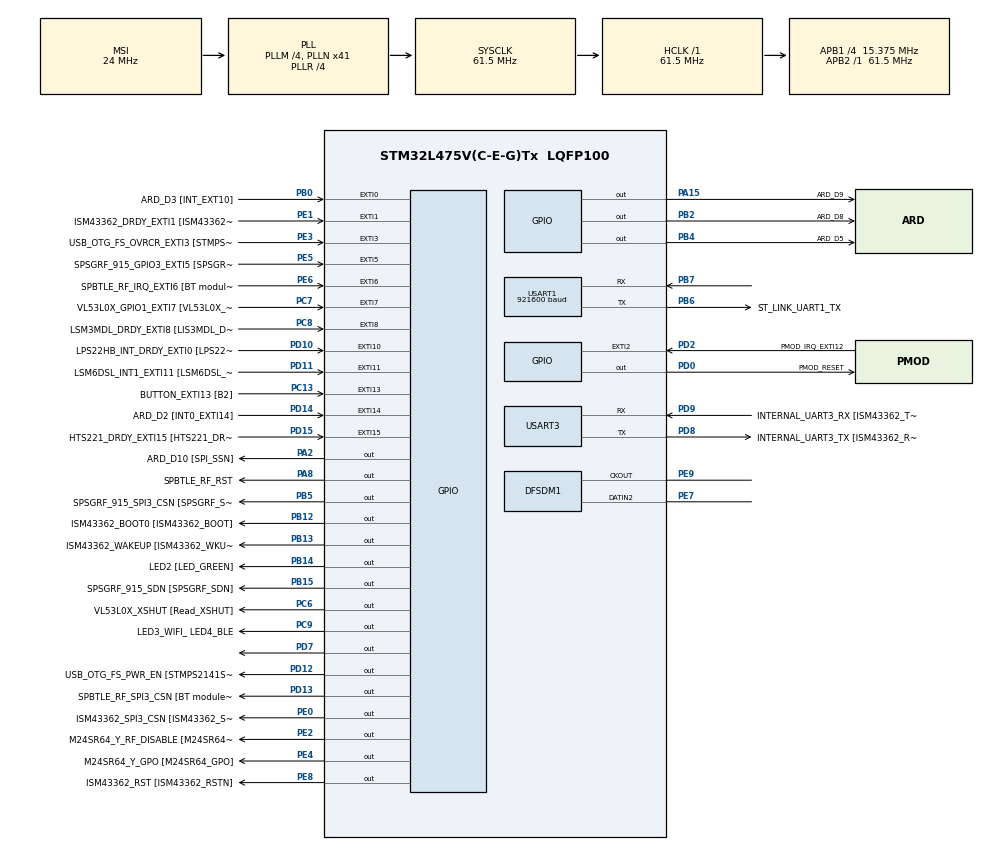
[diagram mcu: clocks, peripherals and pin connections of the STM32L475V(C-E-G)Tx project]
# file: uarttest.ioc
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DFSDM1.Divider=20
DFSDM1.DmaMode_reg_FIL0=ENABLE
DFSDM1.FastMode_reg_FIL0=ENABLE
DFSDM1.Filter_regChannel_FIL0=DFSDM_CHANNEL_1
DFSDM1.Fosr_FIL0=64
DFSDM1.Oversampling_CH1=1
DFSDM1.RightBitShift_CH1=0x02
DFSDM1.Selection=DFSDM_CHANNEL_OUTPUT_CLOCK_AUDIO
DFSDM1.SincOrder_FIL0=DFSDM_FILTER_SINC4_ORDER
DFSDM1.SpiClock_internal_CH1=DFSDM_CHANNEL_SPI_CLOCK_INTERNAL_DIV2_FALLING
Dma.DFSDM1_FLT0.0.Direction=DMA_PERIPH_TO_MEMORY
Dma.DFSDM1_FLT0.0.Instance=DMA1_Channel4
Dma.DFSDM1_FLT0.0.MemDataAlignment=DMA_MDATAALIGN_WORD
Dma.DFSDM1_FLT0.0.MemInc=DMA_MINC_ENABLE
Dma.DFSDM1_FLT0.0.Mode=DMA_CIRCULAR
Dma.DFSDM1_FLT0.0.PeriphDataAlignment=DMA_PDATAALIGN_WORD
Dma.DFSDM1_FLT0.0.PeriphInc=DMA_PINC_DISABLE
Dma.DFSDM1_FLT0.0.Priority=DMA_PRIORITY_HIGH
Dma.Request0=DFSDM1_FLT0
Mcu.Family=STM32L4
Mcu.Name=STM32L475V(C-E-G)Tx
Mcu.Package=LQFP100
NVIC.DFSDM1_FLT0_IRQn=true\:0\:0\:false\:false\:true\:true\:true\:true
NVIC.DMA1_Channel4_IRQn=true\:0\:0\:false\:false\:true\:false\:true\:true
NVIC.EXTI15_10_IRQn=true\:0\:0\:false\:false\:true\:true\:true\:true
NVIC.EXTI9_5_IRQn=true\:0\:0\:false\:false\:true\:true\:true\:true
NVIC.PriorityGroup=NVIC_PRIORITYGROUP_4
PA13\ (JTMS-SWDIO).GPIO_Label=SYS_JTMS_SWDIO
PA13\ (JTMS-SWDIO).Mode=Serial_Wire
PA13\ (JTMS-SWDIO).Signal=SYS_JTMS-SWDIO
PA14\ (JTCK-SWCLK).GPIO_Label=SYS_JTCK_SWCLK
PA14\ (JTCK-SWCLK).Mode=Serial_Wire
PA14\ (JTCK-SWCLK).Signal=SYS_JTCK-SWCLK
PA15\ (JTDI).GPIO_Label=ARD_D9
PA15\ (JTDI).Signal=GPIO_Output
PA2.GPIO_Label=ARD_D10 [SPI_SSN]
PA2.Signal=GPIO_Output
PA8.GPIO_Label=SPBTLE_RF_RST
PA8.Signal=GPIO_Output
PB0.GPIO_Label=ARD_D3 [INT_EXT10]
PB0.Signal=GPXTI0
PB12.GPIO_Label=ISM43362_BOOT0 [ISM43362_BOOT]
PB12.Signal=GPIO_Output
PB13.GPIO_Label=ISM43362_WAKEUP [ISM43362_WKUP]
PB13.Signal=GPIO_Output
PB14.GPIO_Label=LED2 [LED_GREEN]
PB14.Signal=GPIO_Output
PB15.GPIO_Label=SPSGRF_915_SDN [SPSGRF_SDN]
PB15.Signal=GPIO_Output
PB2.GPIO_Label=ARD_D8
PB2.Signal=GPIO_Output
PB4\ (NJTRST).GPIO_Label=ARD_D5
PB4\ (NJTRST).Signal=GPIO_Output
PB5.GPIO_Label=SPSGRF_915_SPI3_CSN [SPSGRF_SPI_CS]
PB5.PinState=GPIO_PIN_SET
PB5.Signal=GPIO_Output
PB6.GPIO_Label=ST_LINK_UART1_TX
PB6.Mode=Asynchronous
PB6.Signal=USART1_TX
PB7.Mode=Asynchronous
PB7.Signal=USART1_RX
PC13.GPIO_Label=BUTTON_EXTI13 [B2]
PC13.GPIO_ModeDefaultEXTI=GPIO_MODE_IT_FALLING
PC13.Signal=GPXTI13
PC14-OSC32_IN\ (PC14).Mode=LSE-External-Oscillator
PC14-OSC32_IN\ (PC14).Signal=RCC_OSC32_IN
PC15-OSC32_OUT\ (PC15).Mode=LSE-External-Oscillator
PC15-OSC32_OUT\ (PC15).Signal=RCC_OSC32_OUT
PC6.GPIO_Label=VL53L0X_XSHUT [Read_XSHUT]
PC6.Signal=GPIO_Output
PC7.GPIO_Label=VL53L0X_GPIO1_EXTI7 [VL53L0X_GPIO1]
PC7.Signal=GPXTI7
PC8.GPIO_Label=LSM3MDL_DRDY_EXTI8 [LIS3MDL_DRDY]
PC8.Signal=GPXTI8
PC9.GPIO_Label=LED3_WIFI_ LED4_BLE
PC9.Signal=GPIO_Output
PD0.GPIO_Label=PMOD_RESET
PD0.Signal=GPIO_Output
PD10.GPIO_Label=LPS22HB_INT_DRDY_EXTI0 [LPS22HB_INT_DRDY] 
PD10.Signal=GPXTI10
PD11.GPIO_Label=LSM6DSL_INT1_EXTI11 [LSM6DSL_INT1]
PD11.Signal=GPXTI11
PD12.GPIO_Label=USB_OTG_FS_PWR_EN [STMPS2141STR_EN]
PD12.Signal=GPIO_Output
PD13.GPIO_Label=SPBTLE_RF_SPI3_CSN [BT module_SPI_CS]
PD13.PinState=GPIO_PIN_SET
PD13.Signal=GPIO_Output
PD14.GPIO_Label=ARD_D2 [INT0_EXTI14]
PD14.Signal=GPXTI14
PD15.GPIO_Label=HTS221_DRDY_EXTI15 [HTS221_DRDY]
PD15.Signal=GPXTI15
PD2.GPIO_Label=PMOD_IRQ_EXTI12
PD2.Signal=GPXTI2
PD7.Signal=GPIO_Output
PD8.GPIO_Label=INTERNAL_UART3_TX [ISM43362_RX]
PD8.Mode=Asynchronous
PD8.Signal=USART3_TX
PD9.GPIO_Label=INTERNAL_UART3_RX [ISM43362_TX]
PD9.Mode=Asynchronous
PD9.Signal=USART3_RX
PE0.GPIO_Label=ISM43362_SPI3_CSN [ISM43362_SSN]
PE0.PinState=GPIO_PIN_SET
PE0.Signal=GPIO_Output
PE1.GPIO_Label=ISM43362_DRDY_EXTI1 [ISM43362_DATARDY]
PE1.Signal=GPXTI1
PE2.GPIO_Label=M24SR64_Y_RF_DISABLE [M24SR64_RFDIS]
PE2.Signal=GPIO_Output
PE3.GPIO_Label=USB_OTG_FS_OVRCR_EXTI3 [STMPS2141STR_FAULT]
PE3.Signal=GPXTI3
PE4.GPIO_Label=M24SR64_Y_GPO [M24SR64_GPO]
PE4.Signal=GPIO_Output
PE5.GPIO_Label=SPSGRF_915_GPIO3_EXTI5 [SPSGRF_GPIO_3]
PE5.Signal=GPXTI5
PE6.GPIO_Label=SPBTLE_RF_IRQ_EXTI6 [BT module_SPI_IRQ]
PE6.Signal=GPXTI6
PE7.Signal=S_DATAIN2DFSDM1
PE8.GPIO_Label=ISM43362_RST [ISM43362_RSTN]
PE8.Signal=GPIO_Output
PE9.Signal=S_CKOUTDFSDM1
ProjectManager.HeapSize=0x200
ProjectManager.StackSize=0x400
ProjectManager.TargetToolchain=STM32CubeIDE
RCC.ADCFreq_Value=33000000
RCC.AHBFreq_Value=61500000
RCC.APB1CLKDivider=RCC_HCLK_DIV4
RCC.APB1Freq_Value=15375000
RCC.APB1TimFreq_Value=30750000
RCC.APB2Freq_Value=61500000
RCC.APB2TimFreq_Value=61500000
RCC.CortexFreq_Value=61500000
RCC.HCLKFreq_Value=61500000
RCC.HSE_VALUE=8000000
RCC.HSI_VALUE=16000000
RCC.MSIClockRange=RCC_MSIRANGE_9
RCC.MSI_VALUE=24000000
RCC.PLLM=4
RCC.PLLN=41
RCC.PLLR=RCC_PLLR_DIV4
RCC.PLLSAI1N=11
RCC.SYSCLKFreq_VALUE=61500000
RCC.SYSCLKSource=RCC_SYSCLKSOURCE_PLLCLK
RCC.USART1CLockSelection=RCC_USART1CLKSOURCE_SYSCLK
RCC.USART3CLockSelection=RCC_USART3CLKSOURCE_SYSCLK
RCC.USBFreq_Value=33000000
RCC.VCOOutputFreq_Value=246000000
SH.S_CKOUTDFSDM1.0=DFSDM1_CKOUT
SH.S_CKOUTDFSDM1.1=DFSDM1_CKOUT,PDM_SPI_Input_from_ch12_and_Internal_Clock
SH.S_CKOUTDFSDM1.2=DFSDM1_CKOUT
SH.S_DATAIN2DFSDM1.0=DFSDM1_DATIN2,PDM_SPI_Input_from_ch12_and_Internal_Clock
SH.S_DATAIN2DFSDM1.1=DFSDM1_DATIN2
USART1.BaudRate=921600
USART1.VirtualMode-Asynchronous=VM_ASYNC
USART3.VirtualMode-Asynchronous=VM_ASYNC
VP_CRC_VS_CRC.Mode=CRC_Activate
board=B-L475E-IOT01A2

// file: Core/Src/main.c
/* USER CODE BEGIN Header */
/**
  ******************************************************************************
  * @file           : main.c
  * @brief          : Main program body
  ******************************************************************************
  * @attention
  *
  * Copyright (c) 2024 STMicroelectronics.
  * All rights reserved.
  *
  * This software is licensed under terms that can be found in the LICENSE file
  * in the root directory of this software component.
  * If no LICENSE file comes with this software, it is provided AS-IS.
  *
  ******************************************************************************
  */
/* USER CODE END Header */
#include "main.h"
//////////////////
#include "stm32l4xx_hal.h"
//#include "arm_math.h"

CRC_HandleTypeDef hcrc;

DFSDM_Filter_HandleTypeDef hdfsdm1_filter0;
DFSDM_Channel_HandleTypeDef hdfsdm1_channel1;
DMA_HandleTypeDef hdma_dfsdm1_flt0;

UART_HandleTypeDef huart1;
UART_HandleTypeDef huart3;

void SystemClock_Config(void);
static void MX_GPIO_Init(void);
static void MX_DMA_Init(void);
static void MX_DFSDM1_Init(void);
static void MX_USART1_UART_Init(void);
static void MX_USART3_UART_Init(void);
static void MX_CRC_Init(void);
/* USER CODE BEGIN PFP */

void PDM_to_PCM(int32_t *pdm_data, int16_t *pcm_data, uint16_t pdm_size);
/* USER CODE END PFP */

int main(void)
{

  /* MCU Configuration--------------------------------------------------------*/

  /* Reset of all peripherals, Initializes the Flash interface and the Systick. */
  HAL_Init();

  /* Configure the system clock */
  SystemClock_Config();

  /* Initialize all configured peripherals */
  MX_GPIO_Init();
  MX_DMA_Init();
  MX_DFSDM1_Init();
  MX_USART1_UART_Init();
  MX_USART3_UART_Init();
  MX_CRC_Init();
  /* USER CODE BEGIN 2 */
#define PDM_BUFFER_SIZE 64
#define PCM_BUFFER_SIZE (PDM_BUFFER_SIZE / 4)
int32_t pdm_buffer[PDM_BUFFER_SIZE];
int16_t pcm_buffer[PCM_BUFFER_SIZE];
HAL_DFSDM_FilterRegularStart_DMA(&hdfsdm1_filter0, pdm_buffer, PDM_BUFFER_SIZE);
/* USER CODE END 2 */

  /* Infinite loop */
  while (1)
  {

  }
}
void HAL_DFSDM_FilterRegConvCpltCallback(DFSDM_Filter_HandleTypeDef *hdfsdm_filter) {
    // Convert PDM to PCM
    PDM_to_PCM(pdm_buffer, pcm_buffer, PDM_BUFFER_SIZE);
    // Transmit PCM data via UART1
    HAL_UART_Transmit(&huart1, (uint8_t*)pcm_buffer, sizeof(pcm_buffer), HAL_MAX_DELAY);
}

    void PDM_to_PCM(int32_t *pdm_data, int16_t *pcm_data, uint16_t pdm_size) {
     // Example conversion function (implement as needed)
      for (uint16_t i = 0; i < pdm_size / 4; i++) {
            pcm_data[i] = (int16_t)(pdm_data[i] >> 8); // Simple downsampling
      }
    }

void SystemClock_Config(void)
{
  RCC_OscInitTypeDef RCC_OscInitStruct = {0};
  RCC_ClkInitTypeDef RCC_ClkInitStruct = {0};

  /** Configure the main internal regulator output voltage
  */
  if (HAL_PWREx_ControlVoltageScaling(PWR_REGULATOR_VOLTAGE_SCALE1) != HAL_OK)
  {
    Error_Handler();
  }

  /** Configure LSE Drive Capability
  */
  HAL_PWR_EnableBkUpAccess();
  __HAL_RCC_LSEDRIVE_CONFIG(RCC_LSEDRIVE_LOW);

  /** Initializes the RCC Oscillators according to the specified parameters
  * in the RCC_OscInitTypeDef structure.
  */
  RCC_OscInitStruct.OscillatorType = RCC_OSCILLATORTYPE_LSE|RCC_OSCILLATORTYPE_MSI;
  RCC_OscInitStruct.LSEState = RCC_LSE_ON;
  RCC_OscInitStruct.MSIState = RCC_MSI_ON;
  RCC_OscInitStruct.MSICalibrationValue = 0;
  RCC_OscInitStruct.MSIClockRange = RCC_MSIRANGE_9;
  RCC_OscInitStruct.PLL.PLLState = RCC_PLL_ON;
  RCC_OscInitStruct.PLL.PLLSource = RCC_PLLSOURCE_MSI;
  RCC_OscInitStruct.PLL.PLLM = 4;
  RCC_OscInitStruct.PLL.PLLN = 41;
  RCC_OscInitStruct.PLL.PLLP = RCC_PLLP_DIV7;
  RCC_OscInitStruct.PLL.PLLQ = RCC_PLLQ_DIV2;
  RCC_OscInitStruct.PLL.PLLR = RCC_PLLR_DIV4;
  if (HAL_RCC_OscConfig(&RCC_OscInitStruct) != HAL_OK)
  {
    Error_Handler();
  }

  /** Initializes the CPU, AHB and APB buses clocks
  */
  RCC_ClkInitStruct.ClockType = RCC_CLOCKTYPE_HCLK|RCC_CLOCKTYPE_SYSCLK
                              |RCC_CLOCKTYPE_PCLK1|RCC_CLOCKTYPE_PCLK2;
  RCC_ClkInitStruct.SYSCLKSource = RCC_SYSCLKSOURCE_PLLCLK;
  RCC_ClkInitStruct.AHBCLKDivider = RCC_SYSCLK_DIV1;
  RCC_ClkInitStruct.APB1CLKDivider = RCC_HCLK_DIV4;
  RCC_ClkInitStruct.APB2CLKDivider = RCC_HCLK_DIV1;

  if (HAL_RCC_ClockConfig(&RCC_ClkInitStruct, FLASH_LATENCY_3) != HAL_OK)
  {
    Error_Handler();
  }

  /** Enable MSI Auto calibration
  */
  HAL_RCCEx_EnableMSIPLLMode();
}

static void MX_CRC_Init(void)
{

  hcrc.Instance = CRC;
  hcrc.Init.DefaultPolynomialUse = DEFAULT_POLYNOMIAL_ENABLE;
  hcrc.Init.DefaultInitValueUse = DEFAULT_INIT_VALUE_ENABLE;
  hcrc.Init.InputDataInversionMode = CRC_INPUTDATA_INVERSION_NONE;
  hcrc.Init.OutputDataInversionMode = CRC_OUTPUTDATA_INVERSION_DISABLE;
  hcrc.InputDataFormat = CRC_INPUTDATA_FORMAT_BYTES;
  if (HAL_CRC_Init(&hcrc) != HAL_OK)
  {
    Error_Handler();
  }

}

static void MX_DFSDM1_Init(void)
{

  hdfsdm1_filter0.Instance = DFSDM1_Filter0;
  hdfsdm1_filter0.Init.RegularParam.Trigger = DFSDM_FILTER_SW_TRIGGER;
  hdfsdm1_filter0.Init.RegularParam.FastMode = ENABLE;
  hdfsdm1_filter0.Init.RegularParam.DmaMode = ENABLE;
  hdfsdm1_filter0.Init.FilterParam.SincOrder = DFSDM_FILTER_SINC4_ORDER;
  hdfsdm1_filter0.Init.FilterParam.Oversampling = 64;
  hdfsdm1_filter0.Init.FilterParam.IntOversampling = 1;
  if (HAL_DFSDM_FilterInit(&hdfsdm1_filter0) != HAL_OK)
  {
    Error_Handler();
  }
  hdfsdm1_channel1.Instance = DFSDM1_Channel1;
  hdfsdm1_channel1.Init.OutputClock.Activation = ENABLE;
  hdfsdm1_channel1.Init.OutputClock.Selection = DFSDM_CHANNEL_OUTPUT_CLOCK_AUDIO;
  hdfsdm1_channel1.Init.OutputClock.Divider = 20;
  hdfsdm1_channel1.Init.Input.Multiplexer = DFSDM_CHANNEL_EXTERNAL_INPUTS;
  hdfsdm1_channel1.Init.Input.DataPacking = DFSDM_CHANNEL_STANDARD_MODE;
  hdfsdm1_channel1.Init.Input.Pins = DFSDM_CHANNEL_FOLLOWING_CHANNEL_PINS;
  hdfsdm1_channel1.Init.SerialInterface.Type = DFSDM_CHANNEL_SPI_RISING;
  hdfsdm1_channel1.Init.SerialInterface.SpiClock = DFSDM_CHANNEL_SPI_CLOCK_INTERNAL_DIV2_FALLING;
  hdfsdm1_channel1.Init.Awd.FilterOrder = DFSDM_CHANNEL_FASTSINC_ORDER;
  hdfsdm1_channel1.Init.Awd.Oversampling = 1;
  hdfsdm1_channel1.Init.Offset = 0;
  hdfsdm1_channel1.Init.RightBitShift = 0x02;
  if (HAL_DFSDM_ChannelInit(&hdfsdm1_channel1) != HAL_OK)
  {
    Error_Handler();
  }
  if (HAL_DFSDM_FilterConfigRegChannel(&hdfsdm1_filter0, DFSDM_CHANNEL_1, DFSDM_CONTINUOUS_CONV_ON) != HAL_OK)
  {
    Error_Handler();
  }

}

static void MX_USART1_UART_Init(void)
{

  huart1.Instance = USART1;
  huart1.Init.BaudRate = 921600;
  huart1.Init.WordLength = UART_WORDLENGTH_8B;
  huart1.Init.StopBits = UART_STOPBITS_1;
  huart1.Init.Parity = UART_PARITY_NONE;
  huart1.Init.Mode = UART_MODE_TX_RX;
  huart1.Init.HwFlowCtl = UART_HWCONTROL_NONE;
  huart1.Init.OverSampling = UART_OVERSAMPLING_16;
  huart1.Init.OneBitSampling = UART_ONE_BIT_SAMPLE_DISABLE;
  huart1.AdvancedInit.AdvFeatureInit = UART_ADVFEATURE_NO_INIT;
  if (HAL_UART_Init(&huart1) != HAL_OK)
  {
    Error_Handler();
  }

}

static void MX_USART3_UART_Init(void)
{

  huart3.Instance = USART3;
  huart3.Init.BaudRate = 115200;
  huart3.Init.WordLength = UART_WORDLENGTH_8B;
  huart3.Init.StopBits = UART_STOPBITS_1;
  huart3.Init.Parity = UART_PARITY_NONE;
  huart3.Init.Mode = UART_MODE_TX_RX;
  huart3.Init.HwFlowCtl = UART_HWCONTROL_NONE;
  huart3.Init.OverSampling = UART_OVERSAMPLING_16;
  huart3.Init.OneBitSampling = UART_ONE_BIT_SAMPLE_DISABLE;
  huart3.AdvancedInit.AdvFeatureInit = UART_ADVFEATURE_NO_INIT;
  if (HAL_UART_Init(&huart3) != HAL_OK)
  {
    Error_Handler();
  }

}

static void MX_DMA_Init(void)
{

  /* DMA controller clock enable */
  __HAL_RCC_DMA1_CLK_ENABLE();

  /* DMA interrupt init */
  /* DMA1_Channel4_IRQn interrupt configuration */
  HAL_NVIC_SetPriority(DMA1_Channel4_IRQn, 0, 0);
  HAL_NVIC_EnableIRQ(DMA1_Channel4_IRQn);

}

static void MX_GPIO_Init(void)
{
  GPIO_InitTypeDef GPIO_InitStruct = {0};

  /* GPIO Ports Clock Enable */
  __HAL_RCC_GPIOE_CLK_ENABLE();
  __HAL_RCC_GPIOC_CLK_ENABLE();
  __HAL_RCC_GPIOA_CLK_ENABLE();
  __HAL_RCC_GPIOB_CLK_ENABLE();
  __HAL_RCC_GPIOD_CLK_ENABLE();

  /*Configure GPIO pin Output Level */
  HAL_GPIO_WritePin(GPIOE, M24SR64_Y_RF_DISABLE_Pin|M24SR64_Y_GPO_Pin|ISM43362_RST_Pin, GPIO_PIN_RESET);

  /*Configure GPIO pin Output Level */
  HAL_GPIO_WritePin(GPIOA, ARD_D10_Pin|SPBTLE_RF_RST_Pin|ARD_D9_Pin, GPIO_PIN_RESET);

  /*Configure GPIO pin Output Level */
  HAL_GPIO_WritePin(GPIOB, ARD_D8_Pin|ISM43362_BOOT0_Pin|ISM43362_WAKEUP_Pin|LED2_Pin
                          |SPSGRF_915_SDN_Pin|ARD_D5_Pin, GPIO_PIN_RESET);

  /*Configure GPIO pin Output Level */
  HAL_GPIO_WritePin(GPIOD, USB_OTG_FS_PWR_EN_Pin|PMOD_RESET_Pin|GPIO_PIN_7, GPIO_PIN_RESET);

  /*Configure GPIO pin Output Level */
  HAL_GPIO_WritePin(SPBTLE_RF_SPI3_CSN_GPIO_Port, SPBTLE_RF_SPI3_CSN_Pin, GPIO_PIN_SET);

  /*Configure GPIO pin Output Level */
  HAL_GPIO_WritePin(GPIOC, VL53L0X_XSHUT_Pin|LED3_WIFI__LED4_BLE_Pin, GPIO_PIN_RESET);

  /*Configure GPIO pin Output Level */
  HAL_GPIO_WritePin(SPSGRF_915_SPI3_CSN_GPIO_Port, SPSGRF_915_SPI3_CSN_Pin, GPIO_PIN_SET);

  /*Configure GPIO pin Output Level */
  HAL_GPIO_WritePin(ISM43362_SPI3_CSN_GPIO_Port, ISM43362_SPI3_CSN_Pin, GPIO_PIN_SET);

  /*Configure GPIO pins : M24SR64_Y_RF_DISABLE_Pin M24SR64_Y_GPO_Pin ISM43362_RST_Pin ISM43362_SPI3_CSN_Pin */
  GPIO_InitStruct.Pin = M24SR64_Y_RF_DISABLE_Pin|M24SR64_Y_GPO_Pin|ISM43362_RST_Pin|ISM43362_SPI3_CSN_Pin;
  GPIO_InitStruct.Mode = GPIO_MODE_OUTPUT_PP;
  GPIO_InitStruct.Pull = GPIO_NOPULL;
  GPIO_InitStruct.Speed = GPIO_SPEED_FREQ_LOW;
  HAL_GPIO_Init(GPIOE, &GPIO_InitStruct);

  /*Configure GPIO pins : USB_OTG_FS_OVRCR_EXTI3_Pin SPSGRF_915_GPIO3_EXTI5_Pin SPBTLE_RF_IRQ_EXTI6_Pin ISM43362_DRDY_EXTI1_Pin */
  GPIO_InitStruct.Pin = USB_OTG_FS_OVRCR_EXTI3_Pin|SPSGRF_915_GPIO3_EXTI5_Pin|SPBTLE_RF_IRQ_EXTI6_Pin|ISM43362_DRDY_EXTI1_Pin;
  GPIO_InitStruct.Mode = GPIO_MODE_IT_RISING;
  GPIO_InitStruct.Pull = GPIO_NOPULL;
  HAL_GPIO_Init(GPIOE, &GPIO_InitStruct);

  /*Configure GPIO pin : BUTTON_EXTI13_Pin */
  GPIO_InitStruct.Pin = BUTTON_EXTI13_Pin;
  GPIO_InitStruct.Mode = GPIO_MODE_IT_FALLING;
  GPIO_InitStruct.Pull = GPIO_NOPULL;
  HAL_GPIO_Init(BUTTON_EXTI13_GPIO_Port, &GPIO_InitStruct);

  /*Configure GPIO pins : ARD_D10_Pin SPBTLE_RF_RST_Pin ARD_D9_Pin */
  GPIO_InitStruct.Pin = ARD_D10_Pin|SPBTLE_RF_RST_Pin|ARD_D9_Pin;
  GPIO_InitStruct.Mode = GPIO_MODE_OUTPUT_PP;
  GPIO_InitStruct.Pull = GPIO_NOPULL;
  GPIO_InitStruct.Speed = GPIO_SPEED_FREQ_LOW;
  HAL_GPIO_Init(GPIOA, &GPIO_InitStruct);

  /*Configure GPIO pin : ARD_D3_Pin */
  GPIO_InitStruct.Pin = ARD_D3_Pin;
  GPIO_InitStruct.Mode = GPIO_MODE_IT_RISING;
  GPIO_InitStruct.Pull = GPIO_NOPULL;
  HAL_GPIO_Init(ARD_D3_GPIO_Port, &GPIO_InitStruct);

  /*Configure GPIO pins : ARD_D8_Pin ISM43362_BOOT0_Pin ISM43362_WAKEUP_Pin LED2_Pin
                           SPSGRF_915_SDN_Pin ARD_D5_Pin SPSGRF_915_SPI3_CSN_Pin */
  GPIO_InitStruct.Pin = ARD_D8_Pin|ISM43362_BOOT0_Pin|ISM43362_WAKEUP_Pin|LED2_Pin
                          |SPSGRF_915_SDN_Pin|ARD_D5_Pin|SPSGRF_915_SPI3_CSN_Pin;
  GPIO_InitStruct.Mode = GPIO_MODE_OUTPUT_PP;
  GPIO_InitStruct.Pull = GPIO_NOPULL;
  GPIO_InitStruct.Speed = GPIO_SPEED_FREQ_LOW;
  HAL_GPIO_Init(GPIOB, &GPIO_InitStruct);

  /*Configure GPIO pins : LPS22HB_INT_DRDY_EXTI0_Pin LSM6DSL_INT1_EXTI11_Pin ARD_D2_Pin HTS221_DRDY_EXTI15_Pin
                           PMOD_IRQ_EXTI12_Pin */
  GPIO_InitStruct.Pin = LPS22HB_INT_DRDY_EXTI0_Pin|LSM6DSL_INT1_EXTI11_Pin|ARD_D2_Pin|HTS221_DRDY_EXTI15_Pin
                          |PMOD_IRQ_EXTI12_Pin;
  GPIO_InitStruct.Mode = GPIO_MODE_IT_RISING;
  GPIO_InitStruct.Pull = GPIO_NOPULL;
  HAL_GPIO_Init(GPIOD, &GPIO_InitStruct);

  /*Configure GPIO pins : USB_OTG_FS_PWR_EN_Pin SPBTLE_RF_SPI3_CSN_Pin PMOD_RESET_Pin PD7 */
  GPIO_InitStruct.Pin = USB_OTG_FS_PWR_EN_Pin|SPBTLE_RF_SPI3_CSN_Pin|PMOD_RESET_Pin|GPIO_PIN_7;
  GPIO_InitStruct.Mode = GPIO_MODE_OUTPUT_PP;
  GPIO_InitStruct.Pull = GPIO_NOPULL;
  GPIO_InitStruct.Speed = GPIO_SPEED_FREQ_LOW;
  HAL_GPIO_Init(GPIOD, &GPIO_InitStruct);

  /*Configure GPIO pins : VL53L0X_XSHUT_Pin LED3_WIFI__LED4_BLE_Pin */
  GPIO_InitStruct.Pin = VL53L0X_XSHUT_Pin|LED3_WIFI__LED4_BLE_Pin;
  GPIO_InitStruct.Mode = GPIO_MODE_OUTPUT_PP;
  GPIO_InitStruct.Pull = GPIO_NOPULL;
  GPIO_InitStruct.Speed = GPIO_SPEED_FREQ_LOW;
  HAL_GPIO_Init(GPIOC, &GPIO_InitStruct);

  /*Configure GPIO pins : VL53L0X_GPIO1_EXTI7_Pin LSM3MDL_DRDY_EXTI8_Pin */
  GPIO_InitStruct.Pin = VL53L0X_GPIO1_EXTI7_Pin|LSM3MDL_DRDY_EXTI8_Pin;
  GPIO_InitStruct.Mode = GPIO_MODE_IT_RISING;
  GPIO_InitStruct.Pull = GPIO_NOPULL;
  HAL_GPIO_Init(GPIOC, &GPIO_InitStruct);

  /* EXTI interrupt init*/
  HAL_NVIC_SetPriority(EXTI9_5_IRQn, 0, 0);
  HAL_NVIC_EnableIRQ(EXTI9_5_IRQn);

  HAL_NVIC_SetPriority(EXTI15_10_IRQn, 0, 0);
  HAL_NVIC_EnableIRQ(EXTI15_10_IRQn);

}

void Error_Handler(void)
{
  __disable_irq();
  while (1)
  {
  }
}
